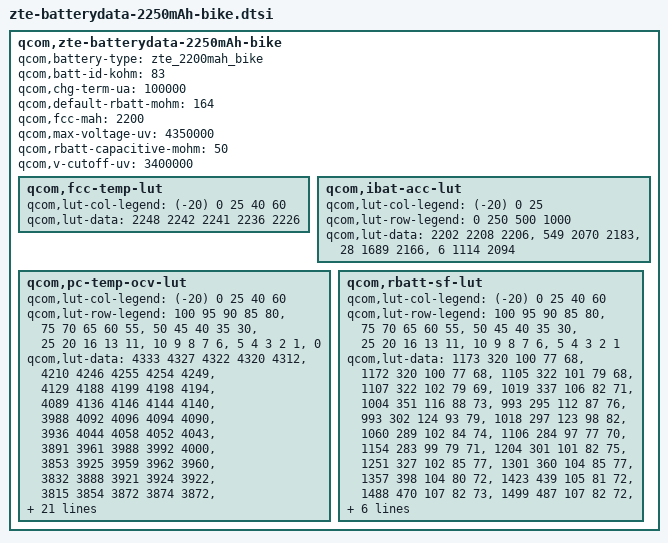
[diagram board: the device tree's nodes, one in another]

qcom,zte-batterydata-2250mAh-bike {
	qcom,battery-type = "zte_2200mah_bike";
	qcom,batt-id-kohm = <83>;
	qcom,chg-term-ua = <100000>;
	qcom,default-rbatt-mohm = <164>;
	qcom,fcc-mah = <2200>;
	qcom,max-voltage-uv = <4350000>;
	qcom,rbatt-capacitive-mohm = <50>;
	qcom,v-cutoff-uv = <3400000>;

	qcom,fcc-temp-lut {
		qcom,lut-col-legend = <(-20) 0 25 40 60>;
		qcom,lut-data = <2248 2242 2241 2236 2226>;
	};

	qcom,ibat-acc-lut {
		qcom,lut-col-legend = <(-20) 0 25>;
		qcom,lut-row-legend = <0 250 500 1000>;
		qcom,lut-data = <2202 2208 2206>,
				<549 2070 2183>,
				<28 1689 2166>,
				<6 1114 2094>;
	};

	qcom,pc-temp-ocv-lut {
		qcom,lut-col-legend = <(-20) 0 25 40 60>;
		qcom,lut-row-legend = <100 95 90 85 80>,
					<75 70 65 60 55>,
					<50 45 40 35 30>,
					<25 20 16 13 11>,
					<10 9 8 7 6>,
					<5 4 3 2 1>,
					<0>;
		qcom,lut-data = <4333 4327 4322 4320 4312>,
				<4210 4246 4255 4254 4249>,
				<4129 4188 4199 4198 4194>,
				<4089 4136 4146 4144 4140>,
				<3988 4092 4096 4094 4090>,
				<3936 4044 4058 4052 4043>,
				<3891 3961 3988 3992 4000>,
				<3853 3925 3959 3962 3960>,
				<3832 3888 3921 3924 3922>,
				<3815 3854 3872 3874 3872>,
				<3802 3824 3840 3841 3840>,
				<3789 3802 3817 3818 3818>,
				<3776 3790 3799 3801 3800>,
				<3763 3782 3784 3785 3784>,
				<3749 3772 3772 3770 3766>,
				<3734 3760 3759 3750 3738>,
				<3716 3742 3740 3731 3718>,
				<3698 3722 3718 3710 3696>,
				<3683 3704 3698 3690 3676>,
				<3671 3696 3690 3683 3671>,
				<3662 3692 3689 3682 3670>,
				<3652 3689 3687 3681 3669>,
				<3641 3686 3686 3679 3668>,
				<3626 3682 3683 3676 3664>,
				<3606 3674 3675 3667 3651>,
				<3582 3654 3649 3639 3618>,
				<3548 3616 3604 3594 3571>,
				<3500 3554 3545 3533 3509>,
				<3421 3472 3463 3450 3424>,
				<3286 3345 3337 3320 3290>,
				<3017 3000 3000 3000 3000>;
	};

	qcom,rbatt-sf-lut {
		qcom,lut-col-legend = <(-20) 0 25 40 60>;
		qcom,lut-row-legend = <100 95 90 85 80>,
					<75 70 65 60 55>,
					<50 45 40 35 30>,
					<25 20 16 13 11>,
					<10 9 8 7 6>,
					<5 4 3 2 1>;
		qcom,lut-data = <1173 320 100 77 68>,
				<1172 320 100 77 68>,
				<1105 322 101 79 68>,
				<1107 322 102 79 69>,
				<1019 337 106 82 71>,
				<1004 351 116 88 73>,
				<993 295 112 87 76>,
				<993 302 124 93 79>,
				<1018 297 123 98 82>,
				<1060 289 102 84 74>,
				<1106 284 97 77 70>,
				<1154 283 99 79 71>,
				<1204 301 101 82 75>,
				<1251 327 102 85 77>,
				<1301 360 104 85 77>,
				<1357 398 104 80 72>,
				<1423 439 105 81 72>,
				<1488 470 107 82 73>,
				<1499 487 107 82 72>,
				<1485 480 105 80 72>,
				<1517 494 107 82 73>,
				<1550 514 110 84 75>,
				<1601 535 113 86 77>,
				<1717 559 118 89 79>,
				<1902 586 122 90 78>,
				<2138 609 119 86 76>,
				<2459 633 120 87 77>,
				<2966 688 124 89 78>,
				<3928 768 134 94 82>,
				<7856 1287 154 111 107>;
	};
};
